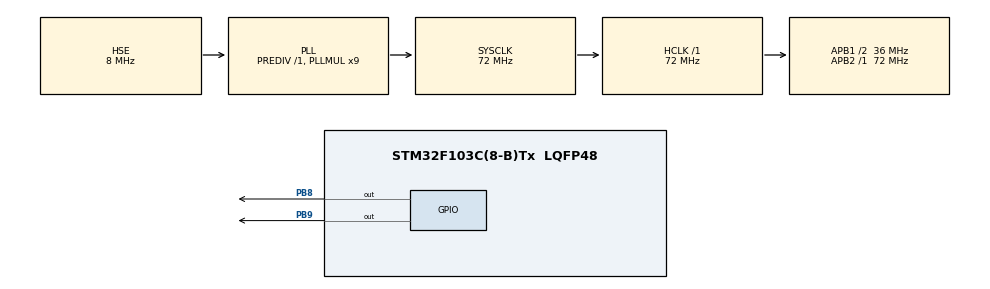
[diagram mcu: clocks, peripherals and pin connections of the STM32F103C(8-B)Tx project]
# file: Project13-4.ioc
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Mcu.Family=STM32F1
Mcu.Name=STM32F103C(8-B)Tx
Mcu.Package=LQFP48
NVIC.PriorityGroup=NVIC_PRIORITYGROUP_4
PA0-WKUP.Mode=SYS_WakeUp0
PA0-WKUP.Signal=SYS_WKUP
PA13.Mode=Serial_Wire
PA13.Signal=SYS_JTMS-SWDIO
PA14.Mode=Serial_Wire
PA14.Signal=SYS_JTCK-SWCLK
PB8.GPIO_ModeDefaultOutputPP=GPIO_MODE_OUTPUT_OD
PB8.GPIO_PuPd=GPIO_NOPULL
PB8.Signal=GPIO_Output
PB9.GPIO_ModeDefaultOutputPP=GPIO_MODE_OUTPUT_OD
PB9.GPIO_PuPd=GPIO_NOPULL
PB9.Signal=GPIO_Output
PC14-OSC32_IN.Mode=LSE-External-Oscillator
PC14-OSC32_IN.Signal=RCC_OSC32_IN
PC15-OSC32_OUT.Mode=LSE-External-Oscillator
PC15-OSC32_OUT.Signal=RCC_OSC32_OUT
PD0-OSC_IN.Mode=HSE-External-Oscillator
PD0-OSC_IN.Signal=RCC_OSC_IN
PD1-OSC_OUT.Mode=HSE-External-Oscillator
PD1-OSC_OUT.Signal=RCC_OSC_OUT
ProjectManager.HeapSize=0x200
ProjectManager.StackSize=0x400
ProjectManager.TargetToolchain=MDK-ARM V5.32
RCC.AHBFreq_Value=72000000
RCC.APB1CLKDivider=RCC_HCLK_DIV2
RCC.APB1Freq_Value=36000000
RCC.APB1TimFreq_Value=72000000
RCC.APB2Freq_Value=72000000
RCC.APB2TimFreq_Value=72000000
RCC.HCLKFreq_Value=72000000
RCC.PLLMUL=RCC_PLL_MUL9
RCC.PLLSourceVirtual=RCC_PLLSOURCE_HSE
RCC.SYSCLKFreq_VALUE=72000000
RCC.SYSCLKSource=RCC_SYSCLKSOURCE_PLLCLK
RCC.USBFreq_Value=72000000
RTC.Date=31
RTC.Format=RTC_FORMAT_BIN
RTC.Hours=11
RTC.Minutes=30
RTC.Month=RTC_MONTH_JULY
RTC.Year=25
VP_RTC_VS_RTC_Activate.Mode=RTC_Enabled
VP_RTC_VS_RTC_Calendar.Mode=RTC_Calendar
board=custom

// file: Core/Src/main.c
/* USER CODE BEGIN Header */
/**
  ******************************************************************************
  * @file           : main.c
  * @brief          : Main program body
  ******************************************************************************
  * @attention
  *
  * Copyright (c) 2025 STMicroelectronics.
  * All rights reserved.
  *
  * This software is licensed under terms that can be found in the LICENSE file
  * in the root directory of this software component.
  * If no LICENSE file comes with this software, it is provided AS-IS.
  *
  ******************************************************************************
  */
/* USER CODE END Header */
#include "main.h"
#include "rtc.h"
#include "gpio.h"

/* USER CODE BEGIN Includes */
#include "OLED.h"
#include <stdint.h>
/* USER CODE END Includes */

/* USER CODE BEGIN PV */
RTC_DateTypeDef RTC_Date;
RTC_TimeTypeDef RTC_Time;
uint32_t rtc_cnt;
/* USER CODE END PV */

void SystemClock_Config(void);

/* USER CODE BEGIN 0 */
void PWR_EnterSTANDBYMode(void)
{
  /* Clear Wake-up flag */
  PWR->CR |= PWR_CR_CWUF;
  /* Select STANDBY mode */
  PWR->CR |= PWR_CR_PDDS;
  /* Set SLEEPDEEP bit of Cortex System Control Register */
  SCB->SCR |= ((uint8_t)0x04);
/* This option is used to ensure that store operations are completed */
#if defined ( __CC_ARM   )
  __force_stores();
#endif
  /* Request Wait For Interrupt */
  __WFI();
}
/* USER CODE END 0 */

int main(void)
{

  /* MCU Configuration--------------------------------------------------------*/

  /* Reset of all peripherals, Initializes the Flash interface and the Systick. */
  HAL_Init();

  /* Configure the system clock */
  SystemClock_Config();

  /* Initialize all configured peripherals */
  MX_GPIO_Init();
  MX_RTC_Init();
  /* USER CODE BEGIN 2 */
  // 模块初始化
  OLED_Init(); // OLED初始化
  //显示静态字符串
  OLED_ShowString(1, 1, "CNT :");
  OLED_ShowString(2, 1, "ALR :");
  OLED_ShowString(3, 1, "ALRF:");
  // 使能WKUP引脚
  HAL_PWR_EnableWakeUpPin(PWR_WAKEUP_PIN1);  // 使能PA0作为唤醒引脚
  // 读取CNT寄存器（计数器值）
  uint8_t alarm;
  OLED_ShowNum(2, 6, alarm, 10);  // 显示闹钟值
  /* USER CODE END 2 */

  /* Infinite loop */
  /* USER CODE BEGIN WHILE */
  while (1)
  {
	 // 读取CNT寄存器（计数器值）
	  rtc_cnt = RTC->CNTH;  // 高16位
	  rtc_cnt <<= 16;       // 偏移
	  rtc_cnt |= RTC->CNTL;  // 低16位，组合成32位计数器值
	  // 显示当前计数器值
     OLED_ShowNum(1,6,rtc_cnt,10);

    // 显示闹钟标志位
    uint8_t alrFlag ;
    OLED_ShowNum(3, 6, alrFlag, 1);

    // 显示运行状态
    OLED_ShowString(4, 1, "Running");
    HAL_Delay(100);
    OLED_ShowString(4, 1, "       ");
    HAL_Delay(100);

    // 显示即将进入待机模式
    OLED_ShowString(4, 9, "STANDBY");
    HAL_Delay(100);
    OLED_ShowString(4, 9, "       ");
    HAL_Delay(100);

    // 清屏，模拟关闭外设省电
    OLED_Clear();
    HAL_SuspendTick();  // 禁用SysTick中断
    // 进入待机模式
    PWR_EnterSTANDBYMode();
	HAL_ResumeTick();  // 重新启用SysTick

    /* USER CODE END WHILE */

  }
}

void SystemClock_Config(void)
{
  RCC_OscInitTypeDef RCC_OscInitStruct = {0};
  RCC_ClkInitTypeDef RCC_ClkInitStruct = {0};
  RCC_PeriphCLKInitTypeDef PeriphClkInit = {0};

  /** Initializes the RCC Oscillators according to the specified parameters
  * in the RCC_OscInitTypeDef structure.
  */
  RCC_OscInitStruct.OscillatorType = RCC_OSCILLATORTYPE_LSI|RCC_OSCILLATORTYPE_HSE;
  RCC_OscInitStruct.HSEState = RCC_HSE_ON;
  RCC_OscInitStruct.HSEPredivValue = RCC_HSE_PREDIV_DIV1;
  RCC_OscInitStruct.HSIState = RCC_HSI_ON;
  RCC_OscInitStruct.LSIState = RCC_LSI_ON;
  RCC_OscInitStruct.PLL.PLLState = RCC_PLL_ON;
  RCC_OscInitStruct.PLL.PLLSource = RCC_PLLSOURCE_HSE;
  RCC_OscInitStruct.PLL.PLLMUL = RCC_PLL_MUL9;
  if (HAL_RCC_OscConfig(&RCC_OscInitStruct) != HAL_OK)
  {
    Error_Handler();
  }

  /** Initializes the CPU, AHB and APB buses clocks
  */
  RCC_ClkInitStruct.ClockType = RCC_CLOCKTYPE_HCLK|RCC_CLOCKTYPE_SYSCLK
                              |RCC_CLOCKTYPE_PCLK1|RCC_CLOCKTYPE_PCLK2;
  RCC_ClkInitStruct.SYSCLKSource = RCC_SYSCLKSOURCE_PLLCLK;
  RCC_ClkInitStruct.AHBCLKDivider = RCC_SYSCLK_DIV1;
  RCC_ClkInitStruct.APB1CLKDivider = RCC_HCLK_DIV2;
  RCC_ClkInitStruct.APB2CLKDivider = RCC_HCLK_DIV1;

  if (HAL_RCC_ClockConfig(&RCC_ClkInitStruct, FLASH_LATENCY_2) != HAL_OK)
  {
    Error_Handler();
  }
  PeriphClkInit.PeriphClockSelection = RCC_PERIPHCLK_RTC;
  PeriphClkInit.RTCClockSelection = RCC_RTCCLKSOURCE_LSI;
  if (HAL_RCCEx_PeriphCLKConfig(&PeriphClkInit) != HAL_OK)
  {
    Error_Handler();
  }
}

void Error_Handler(void)
{
  __disable_irq();
  while (1)
  {
  }
}
